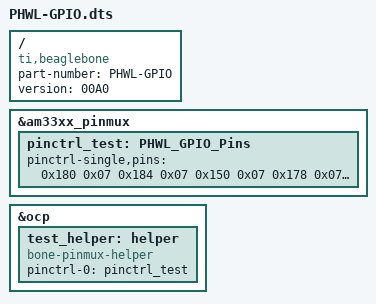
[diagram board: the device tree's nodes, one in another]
/*  
* Copyright (C) 2012 Texas Instruments Incorporated - http://www.ti.com/
*
* This program is free software; you can redistribute it and/or modify
* it under the terms of the GNU General Purpose License Version 2 as
* published by the Free Software Foundation
*
* Original from: github.com/jadonk/validation-scripts/blob/master/test-capemgr/ 
*
* Modified by Derek Molloy for the example on www.derekmolloy.ie
* that maps GPIO pins for the example
*
* Modified by Philip Leong for SSD exercise
*
*/

/dts-v1/;
/plugin/;

/{
       compatible = "ti,beaglebone", "ti,beaglebone-black";
       part-number = "PHWL-GPIO";
       version = "00A0";

       fragment@0 {
             target = <&am33xx_pinmux>;
            
             __overlay__ {
                  pinctrl_test: PHWL_GPIO_Pins {
			pinctrl-single,pins = <

				0x180 0x07  /* P9_26 OUT */
				0x184 0x07  /* P9_24 OUT */
				0x150 0x07  /* P9_22 OUT */
				0x178 0x07  /* P9_20 OUT */
				0x17c 0x07  /* P9_19 OUT */
				0x158 0x07  /* P9_18 OUT */
				0x15c 0x07  /* P9_17 OUT */
				0x074 0x07  /* P9_13 OUT */
				0x0a8 0x37  /* P8_43 PULLUP IN */
                       
                               /* OUTPUT  GPIO(mode7) 0x07 pulldown, 0x17 pullup, 0x?f no pullup/down */
			       /* INPUT   GPIO(mode7) 0x27 pulldown, 0x37 pullup, 0x?f no pullup/down */

			>;
		  };
             };
       };

       fragment@1 {
		target = <&ocp>;
		__overlay__ {
			test_helper: helper {
				compatible = "bone-pinmux-helper";
				pinctrl-names = "default";
				pinctrl-0 = <&pinctrl_test>;
				status = "okay";
			};
		};
	};
};
